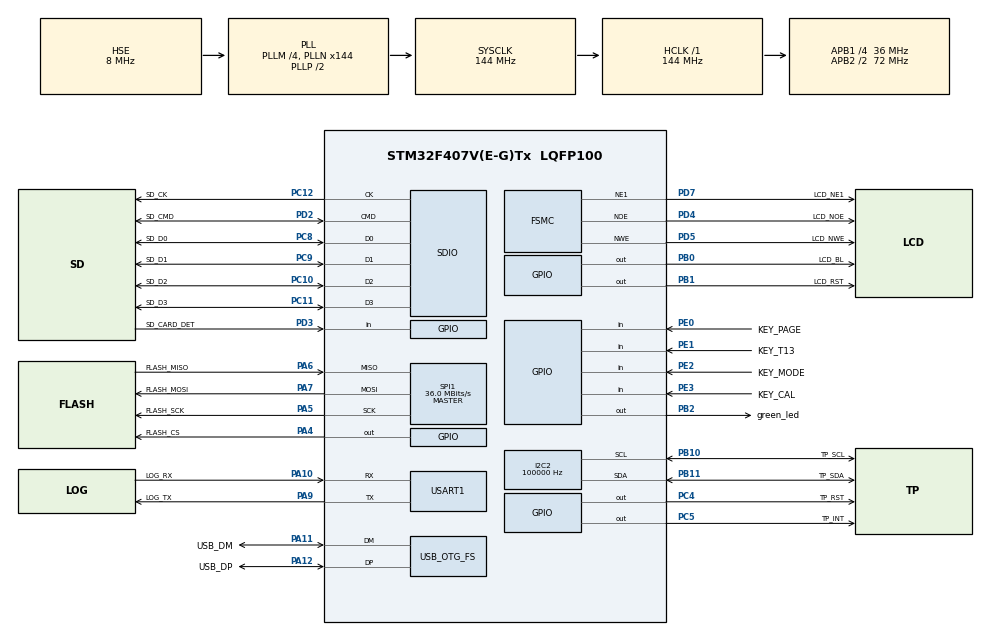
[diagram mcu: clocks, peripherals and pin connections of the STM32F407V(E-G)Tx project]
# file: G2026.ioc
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FREERTOS.Tasks01=defaultTask,24,256,StartDefaultTask,Default,NULL,Dynamic,NULL,NULL
FSMC.AccessMode1-Lcd1=FSMC_ACCESS_MODE_A
FSMC.AccessMode1-NorPsramChipSelect1_1=FSMC_ACCESS_MODE_A
FSMC.AddressHoldTime1-Lcd1=0
FSMC.AddressHoldTime1-NorPsramChipSelect1_1=0
FSMC.AddressSetupTime1-Lcd1=1
FSMC.AddressSetupTime1-NorPsramChipSelect1_1=1
FSMC.BusTurnAroundDuration1-Lcd1=0
FSMC.BusTurnAroundDuration1-NorPsramChipSelect1_1=0
FSMC.CLKDivision1-Lcd1=2
FSMC.CLKDivision1-NorPsramChipSelect1_1=2
FSMC.DataAddressMux1-Lcd1=FSMC_DATA_ADDRESS_MUX_DISABLE
FSMC.DataAddressMux1-NorPsramChipSelect1_1=FSMC_DATA_ADDRESS_MUX_DISABLE
FSMC.DataLatency1-Lcd1=2
FSMC.DataLatency1-NorPsramChipSelect1_1=2
FSMC.DataSetupTime1-Lcd1=15
FSMC.DataSetupTime1-NorPsramChipSelect1_1=15
FSMC.ExtendedMode1-Lcd1=FSMC_EXTENDED_MODE_DISABLE
FSMC.ExtendedMode1-NorPsramChipSelect1_1=FSMC_EXTENDED_MODE_DISABLE
FSMC.MemoryType1-Lcd1=FSMC_MEMORY_TYPE_SRAM
FSMC.MemoryType1-NorPsramChipSelect1_1=FSMC_MEMORY_TYPE_SRAM
FSMC.NSBank1-Lcd1=FSMC_NORSRAM_BANK1
FSMC.NSBank1-NorPsramChipSelect1_1=FSMC_NORSRAM_BANK1
FSMC.NSMemoryDataWidth1-Lcd1=FSMC_NORSRAM_MEM_BUS_WIDTH_16
FSMC.NSMemoryDataWidth1-NorPsramChipSelect1_1=FSMC_NORSRAM_MEM_BUS_WIDTH_16
FSMC.WriteOperation1-Lcd1=FSMC_WRITE_OPERATION_ENABLE
FSMC.WriteOperation1-NorPsramChipSelect1_1=FSMC_WRITE_OPERATION_ENABLE
I2C2.AddressingMode=I2C_ADDRESSINGMODE_7BIT
I2C2.ClockSpeed=100000
I2C2.DualAddressMode=I2C_DUALADDRESS_DISABLE
I2C2.GeneralCallMode=I2C_GENERALCALL_DISABLE
I2C2.I2C_Mode=I2C_MODE_I2C
I2C2.I2C_Speed_Mode=I2C_SPEED_MODE_STANDARD
I2C2.NoStretchMode=I2C_NOSTRETCH_DISABLE
I2C2.OwnAddress1=0
Mcu.Family=STM32F4
Mcu.Name=STM32F407V(E-G)Tx
Mcu.Package=LQFP100
NVIC.OTG_FS_IRQn=true\:5\:0\:false\:false\:true\:false\:true\:true\:true
NVIC.PriorityGroup=NVIC_PRIORITYGROUP_4
NVIC.SDIO_IRQn=true\:5\:0\:false\:false\:true\:false\:true\:true\:true
NVIC.TIM6_DAC_IRQn=true\:15\:0\:false\:false\:true\:false\:true\:true\:true
NVIC.TimeBase=TIM6_DAC_IRQn
NVIC.TimeBaseIP=TIM6
PA0-WKUP.GPIO_Label=ADC_IN
PA0-WKUP.Signal=ADCx_IN0
PA10.GPIO_Label=LOG_RX
PA10.Mode=Asynchronous
PA10.Signal=USART1_RX
PA11.GPIO_Label=USB_DM
PA11.Mode=Device_Only
PA11.Signal=USB_OTG_FS_DM
PA12.GPIO_Label=USB_DP
PA12.Mode=Device_Only
PA12.Signal=USB_OTG_FS_DP
PA13.GPIO_Label=SWDIO
PA13.Mode=Serial_Wire
PA13.Signal=SYS_JTMS-SWDIO
PA14.GPIO_Label=SWCLK
PA14.Mode=Serial_Wire
PA14.Signal=SYS_JTCK-SWCLK
PA4.GPIO_Label=FLASH_CS
PA4.PinState=GPIO_PIN_SET
PA4.Signal=GPIO_Output
PA5.GPIO_Label=FLASH_SCK
PA5.Mode=Full_Duplex_Master
PA5.Signal=SPI1_SCK
PA6.GPIO_Label=FLASH_MISO
PA6.Mode=Full_Duplex_Master
PA6.Signal=SPI1_MISO
PA7.GPIO_Label=FLASH_MOSI
PA7.Mode=Full_Duplex_Master
PA7.Signal=SPI1_MOSI
PA9.GPIO_Label=LOG_TX
PA9.Mode=Asynchronous
PA9.Signal=USART1_TX
PB0.GPIO_Label=LCD_BL
PB0.PinState=GPIO_PIN_RESET
PB0.Signal=GPIO_Output
PB1.GPIO_Label=LCD_RST
PB1.PinState=GPIO_PIN_SET
PB1.Signal=GPIO_Output
PB10.GPIO_Label=TP_SCL
PB10.Mode=I2C
PB10.Signal=I2C2_SCL
PB11.GPIO_Label=TP_SDA
PB11.Mode=I2C
PB11.Signal=I2C2_SDA
PB2.GPIO_Label=green_led
PB2.PinState=GPIO_PIN_RESET
PB2.Signal=GPIO_Output
PC10.GPIO_Label=SD_D2
PC10.Mode=SD_4_bits_Wide_bus
PC10.Signal=SDIO_D2
PC11.GPIO_Label=SD_D3
PC11.Mode=SD_4_bits_Wide_bus
PC11.Signal=SDIO_D3
PC12.GPIO_Label=SD_CK
PC12.Mode=SD_4_bits_Wide_bus
PC12.Signal=SDIO_CK
PC14-OSC32_IN.GPIO_Label=LSE_IN
PC14-OSC32_IN.Mode=LSE-External-Oscillator
PC14-OSC32_IN.Signal=RCC_OSC32_IN
PC15-OSC32_OUT.GPIO_Label=LSE_OUT
PC15-OSC32_OUT.Mode=LSE-External-Oscillator
PC15-OSC32_OUT.Signal=RCC_OSC32_OUT
PC4.GPIO_Label=TP_RST
PC4.PinState=GPIO_PIN_SET
PC4.Signal=GPIO_Output
PC5.GPIO_Label=TP_INT
PC5.PinState=GPIO_PIN_RESET
PC5.Signal=GPIO_Output
PC8.GPIO_Label=SD_D0
PC8.Mode=SD_4_bits_Wide_bus
PC8.Signal=SDIO_D0
PC9.GPIO_Label=SD_D1
PC9.Mode=SD_4_bits_Wide_bus
PC9.Signal=SDIO_D1
PD0.GPIO_Label=LCD_D2
PD0.Signal=FSMC_D2
PD1.GPIO_Label=LCD_D3
PD1.Signal=FSMC_D3
PD10.GPIO_Label=LCD_D15
PD10.Signal=FSMC_D15
PD11.GPIO_Label=LCD_A16
PD11.Signal=FSMC_A16
PD14.GPIO_Label=LCD_D0
PD14.Signal=FSMC_D0
PD15.GPIO_Label=LCD_D1
PD15.Signal=FSMC_D1
PD2.GPIO_Label=SD_CMD
PD2.Mode=SD_4_bits_Wide_bus
PD2.Signal=SDIO_CMD
PD3.GPIO_Label=SD_CARD_DET
PD3.GPIO_PuPd=GPIO_PULLUP
PD3.Signal=GPIO_Input
PD4.GPIO_Label=LCD_NOE
PD4.Mode=Lcd1
PD4.Signal=FSMC_NOE
PD5.GPIO_Label=LCD_NWE
PD5.Mode=Lcd1
PD5.Signal=FSMC_NWE
PD7.GPIO_Label=LCD_NE1
PD7.Mode=NorPsramChipSelect1_1
PD7.Signal=FSMC_NE1
PD8.GPIO_Label=LCD_D13
PD8.Signal=FSMC_D13
PD9.GPIO_Label=LCD_D14
PD9.Signal=FSMC_D14
PE0.GPIO_Label=KEY_PAGE
PE0.GPIO_PuPd=GPIO_PULLUP
PE0.Signal=GPIO_Input
PE1.GPIO_Label=KEY_T13
PE1.GPIO_PuPd=GPIO_PULLUP
PE1.Signal=GPIO_Input
PE10.GPIO_Label=LCD_D7
PE10.Signal=FSMC_D7
PE11.GPIO_Label=LCD_D8
PE11.Signal=FSMC_D8
PE12.GPIO_Label=LCD_D9
PE12.Signal=FSMC_D9
PE13.GPIO_Label=LCD_D10
PE13.Signal=FSMC_D10
PE14.GPIO_Label=LCD_D11
PE14.Signal=FSMC_D11
PE15.GPIO_Label=LCD_D12
PE15.Signal=FSMC_D12
PE2.GPIO_Label=KEY_MODE
PE2.GPIO_PuPd=GPIO_PULLUP
PE2.Signal=GPIO_Input
PE3.GPIO_Label=KEY_CAL
PE3.GPIO_PuPd=GPIO_PULLUP
PE3.Signal=GPIO_Input
PE7.GPIO_Label=LCD_D4
PE7.Signal=FSMC_D4
PE8.GPIO_Label=LCD_D5
PE8.Signal=FSMC_D5
PE9.GPIO_Label=LCD_D6
PE9.Signal=FSMC_D6
PH0-OSC_IN.GPIO_Label=HSE_IN
PH0-OSC_IN.Mode=HSE-External-Oscillator
PH0-OSC_IN.Signal=RCC_OSC_IN
PH1-OSC_OUT.GPIO_Label=HSE_OUT
PH1-OSC_OUT.Mode=HSE-External-Oscillator
PH1-OSC_OUT.Signal=RCC_OSC_OUT
ProjectManager.HeapSize=0x200
ProjectManager.StackSize=0x400
ProjectManager.TargetToolchain=CMake
RCC.48MHZClocksFreq_Value=48000000
RCC.AHBFreq_Value=144000000
RCC.APB1CLKDivider=RCC_HCLK_DIV4
RCC.APB1Freq_Value=36000000
RCC.APB1TimFreq_Value=72000000
RCC.APB2CLKDivider=RCC_HCLK_DIV2
RCC.APB2Freq_Value=72000000
RCC.APB2TimFreq_Value=144000000
RCC.CortexFreq_Value=144000000
RCC.HCLKFreq_Value=144000000
RCC.HSE_VALUE=8000000
RCC.HSI_VALUE=16000000
RCC.PLLM=4
RCC.PLLN=144
RCC.PLLQ=6
RCC.RCC_RTC_Clock_Source=RCC_RTCCLKSOURCE_LSE
RCC.RCC_RTC_Clock_SourceVirtual=RCC_RTCCLKSOURCE_LSE
RCC.RTCClockSelection=RCC_RTCCLKSOURCE_LSE
RCC.RTCClockSelectionARG=RCC_RTCCLKSOURCE_LSE
RCC.SYSCLKFreq_VALUE=144000000
RCC.SYSCLKSource=RCC_SYSCLKSOURCE_PLLCLK
RCC.VCOOutputFreq_Value=288000000
SDIO.ClockDiv=0
SDIO.VirtualMode=SD_4_bits_Wide_bus
SPI1.CalculateBaudRate=36.0 MBits/s
SPI1.Direction=SPI_DIRECTION_2LINES
SPI1.Mode=SPI_MODE_MASTER
SPI1.VirtualType=VM_MASTER
STMicroelectronics.X-CUBE-ALGOBUILD.1.5.0.LibraryCcDSPOoLibraryJjDSPOoLibrary=true
TIM8.ClockDivision=TIM_CLOCKDIVISION_DIV1
TIM8.CounterMode=TIM_COUNTERMODE_UP
TIM8.Period=71
TIM8.Prescaler=0
TIM8.TIM_MasterOutputTrigger=TIM_TRGO_UPDATE
USART1.VirtualMode=VM_ASYNC
USB_OTG_FS.VirtualMode=Device_Only
VP_FREERTOS_VS_CMSIS_V2.Mode=CMSIS_V2
VP_RTC_VS_RTC_Activate.Mode=RTC_Enabled
VP_STMicroelectronics.X-CUBE-ALGOBUILD_VS_DSPOoLibraryJjLibrary_1.5.0_1.5.0.Mode=DSPOoLibraryJjLibrary
VP_SYS_VS_tim6.Mode=TIM6
VP_TIM8_VS_ClockSourceINT.Mode=Internal
board=custom

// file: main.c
/* USER CODE BEGIN Header */
/**
  ******************************************************************************
  * @file           : main.c
  * @brief          : Main program body
  ******************************************************************************
  * @attention
  *
  * Copyright (c) 2026 STMicroelectronics.
  * All rights reserved.
  *
  * This software is licensed under terms that can be found in the LICENSE file
  * in the root directory of this software component.
  * If no LICENSE file comes with this software, it is provided AS-IS.
  *
  ******************************************************************************
  */
/* USER CODE END Header */
#include "main.h"
#include "cmsis_os.h"
#include "i2c.h"
#include "rtc.h"
#include "sdio.h"
#include "spi.h"
#include "tim.h"
#include "usart.h"
#include "usb_otg.h"
#include "gpio.h"
#include "fsmc.h"

/* USER CODE BEGIN Includes */
/* ★ 程序入口。main() 属于 Core/（生成物），它是"启动序列"而不是四层里的一层，
 *   所以"Core 调 Task"不算越层（docs/01 §组合根）。
 *   规矩：这里**只写胶水**，任何逻辑都回 Task/ 层。 */
#include "app.h" /* Task 层：app_init() —— 组合根 */
/* USER CODE END Includes */

void SystemClock_Config(void);
void MX_FREERTOS_Init(void);

int main(void)
{

  /* MCU Configuration--------------------------------------------------------*/

  /* Reset of all peripherals, Initializes the Flash interface and the Systick. */
  HAL_Init();

  /* Configure the system clock */
  SystemClock_Config();

  /* Initialize all configured peripherals */
  MX_GPIO_Init();
  MX_USART1_UART_Init();
  MX_USB_OTG_FS_PCD_Init();
  MX_SPI1_Init();
  MX_SDIO_SD_Init();
  MX_RTC_Init();
  MX_TIM8_Init();
  MX_I2C2_Init();
  MX_FSMC_Init();
  /* USER CODE BEGIN 2 */
  /* ★ 全工程唯一的应用入口。
   *
   * 为什么放在这里（时序上必须是这个位置）：
   *   HAL_Init → SystemClock_Config → MX_*_Init 已完成，硬件都就位了；
   *   而 osKernelInitialize / MX_FREERTOS_Init / osKernelStart 还没调 ——
   *   ⇒ app_init() 运行时**调度器还没启动**，所以它里面不许取任何
   *     FreeRTOS 原语（锁 / 队列 / 延时）。详见 Task/Inc/app.h 的时序说明。
   *
   * ⚠️ 这是 main.c 里唯一该出现的一行业务代码。要加功能就进 Task/ 层。 */
  app_init();
  /* USER CODE END 2 */

  /* Init scheduler */
  osKernelInitialize();  /* Call init function for freertos objects (in cmsis_os2.c) */
  MX_FREERTOS_Init();

  /* Start scheduler */
  osKernelStart();

  /* We should never get here as control is now taken by the scheduler */

  /* Infinite loop */
  while (1)
  {

  }
}

void SystemClock_Config(void)
{
  RCC_OscInitTypeDef RCC_OscInitStruct = {0};
  RCC_ClkInitTypeDef RCC_ClkInitStruct = {0};

  /** Configure the main internal regulator output voltage
  */
  __HAL_RCC_PWR_CLK_ENABLE();
  __HAL_PWR_VOLTAGESCALING_CONFIG(PWR_REGULATOR_VOLTAGE_SCALE1);

  /** Initializes the RCC Oscillators according to the specified parameters
  * in the RCC_OscInitTypeDef structure.
  */
  RCC_OscInitStruct.OscillatorType = RCC_OSCILLATORTYPE_HSE|RCC_OSCILLATORTYPE_LSE;
  RCC_OscInitStruct.HSEState = RCC_HSE_ON;
  RCC_OscInitStruct.LSEState = RCC_LSE_ON;
  RCC_OscInitStruct.PLL.PLLState = RCC_PLL_ON;
  RCC_OscInitStruct.PLL.PLLSource = RCC_PLLSOURCE_HSE;
  RCC_OscInitStruct.PLL.PLLM = 4;
  RCC_OscInitStruct.PLL.PLLN = 144;
  RCC_OscInitStruct.PLL.PLLP = RCC_PLLP_DIV2;
  RCC_OscInitStruct.PLL.PLLQ = 6;
  if (HAL_RCC_OscConfig(&RCC_OscInitStruct) != HAL_OK)
  {
    Error_Handler();
  }

  /** Initializes the CPU, AHB and APB buses clocks
  */
  RCC_ClkInitStruct.ClockType = RCC_CLOCKTYPE_HCLK|RCC_CLOCKTYPE_SYSCLK
                              |RCC_CLOCKTYPE_PCLK1|RCC_CLOCKTYPE_PCLK2;
  RCC_ClkInitStruct.SYSCLKSource = RCC_SYSCLKSOURCE_PLLCLK;
  RCC_ClkInitStruct.AHBCLKDivider = RCC_SYSCLK_DIV1;
  RCC_ClkInitStruct.APB1CLKDivider = RCC_HCLK_DIV4;
  RCC_ClkInitStruct.APB2CLKDivider = RCC_HCLK_DIV2;

  if (HAL_RCC_ClockConfig(&RCC_ClkInitStruct, FLASH_LATENCY_4) != HAL_OK)
  {
    Error_Handler();
  }
}

void HAL_TIM_PeriodElapsedCallback(TIM_HandleTypeDef *htim)
{
  if (htim->Instance == TIM6)
  {
    HAL_IncTick();
  }
}

void Error_Handler(void)
{
  /* USER CODE BEGIN Error_Handler_Debug */
  /* ★ CubeMX 的默认实现是 `__disable_irq(); while(1);` —— **完全无声**。
   *   那时的现象是"板子毫无反应、RTT 一个字都没有"，与"固件没烧进去"
   *   "探针没插"完全无法区分 —— 实测能白查半小时。
   *   ⇒ 至少要把日志后端拉起来（RTT 只要内存，不需要时钟与中断）打一行。
   *
   * ⚠️ 但**不能**用 app_panic（那是"停机"语义）—— 2026-09-23 上板实测：
   *    Error_Handler 会被**所有** HAL 初始化失败调到，其中最常见的是
   *    `MX_SDIO_SD_Init()`：**板子上没插 TF 卡时 `HAL_SD_Init()` 必然失败**，
   *    结果整块板子起不来。实测调用栈：
   *      Reset_Handler → main → MX_SDIO_SD_Init → Error_Handler → app_panic
   *    TF 卡是可选外设，不该绑架启动。
   *
   * ⇒ 改成 app_init_failed()：打一行 ERROR 日志后**返回**，让 main() 继续。
   *   （它故意不打 [AI_FAIL] 标记 —— 那是 fw.py verify 的失败判据，
   *     打了会把"其实跑起来了"误判成失败。） */
  app_init_failed("Error_Handler: HAL 初始化未成功（外设？时钟？HSE 起振？）");
  /* USER CODE END Error_Handler_Debug */
}
